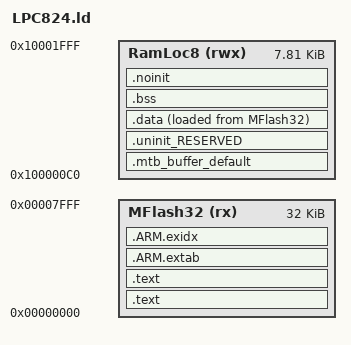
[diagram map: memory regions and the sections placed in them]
/*Based on following file
 * (c) Code Red Technologies Ltd, 2008-13
 * (c) NXP Semiconductors 2013-2015
 * Generated linker script file for LPC824
 * Created from generic_c.ld (LPCXpresso v7.4 (0 [Build 229] [2014-09-16] ))
 * By LPCXpresso v7.4.0 [Build 229] [2014-09-16]  on Fri Jan 02 03:36:48 JST 2015
 */

/* Linker script to configure memory regions. */
MEMORY
{
  /* Define each memory region */
  MFlash32 (rx) : ORIGIN = 0x0, LENGTH = 0x8000 /* 32K bytes */
  RamLoc8 (rwx) : ORIGIN = 0x10000000+0xC0, LENGTH = 0x2000-0xC0 /* 8K bytes */


}

  /* Define a symbol for the top of each memory region */
  __top_MFlash32 = 0x0 + 0x8000;
  __top_RamLoc8 = 0x10000000 + 0x2000;

GROUP(libgcc.a libc.a libstdc++.a libm.a libcr_newlib_nohost.a crti.o crtn.o crtbegin.o crtend.o)
/*GROUP(libcr_nohost.a libcr_c.a libcr_eabihelpers.a libm.a)*/
/* Linker script to place sections and symbol values. Should be used together
 * with other linker script that defines memory regions FLASH and RAM.
 * It references following symbols, which must be defined in code:
 *   Reset_Handler : Entry of reset handler
 * 
 * It defines following symbols, which code can use without definition:
 *   __exidx_start
 *   __exidx_end
 *   __etext
 *   __data_start__
 *   __preinit_array_start
 *   __preinit_array_end
 *   __init_array_start
 *   __init_array_end
 *   __fini_array_start
 *   __fini_array_end
 *   __data_end__
 *   __bss_start__
 *   __bss_end__
 *   __end__
 *   end
 *   __HeapLimit
 *   __StackLimit
 *   __StackTop
 *   __stack
 */
ENTRY(ResetISR)

SECTIONS
{

    /* MAIN TEXT SECTION */    
    .text : ALIGN(4)
    {
        FILL(0xff)
        __vectors_start__ = ABSOLUTE(.) ;
        KEEP(*(.isr_vector))
        
        /* Global Section Table */
        . = ALIGN(4) ;
        __section_table_start = .;
        __data_section_table = .;
        LONG(LOADADDR(.data));
        LONG(    ADDR(.data));
        LONG(  SIZEOF(.data));
        __data_section_table_end = .;
        __bss_section_table = .;
        LONG(    ADDR(.bss));
        LONG(  SIZEOF(.bss));
        __bss_section_table_end = .;
        __section_table_end = . ;
        /* End of Global Section Table */
        

        *(.after_vectors*)        
    } >MFlash32
    
    .text : ALIGN(4)    
    {
         *(.text*)
        *(.rodata .rodata.* .constdata .constdata.*)
        . = ALIGN(4);


        /* C++ constructors etc */
        . = ALIGN(4);
        KEEP(*(.init))
        
        . = ALIGN(4);
        __preinit_array_start = .;
        KEEP (*(.preinit_array))
        __preinit_array_end = .;
        
        . = ALIGN(4);
        __init_array_start = .;
        KEEP (*(SORT(.init_array.*)))
        KEEP (*(.init_array))
        __init_array_end = .;
        
        KEEP(*(.fini));
        
        /* .ctors */
        *crtbegin.o(.ctors)
        *crtbegin?.o(.ctors)
        *(EXCLUDE_FILE(*crtend?.o *crtend.o) .ctors)
        *(SORT(.ctors.*))
        *(.ctors)

        /* .dtors */
        *crtbegin.o(.dtors)
        *crtbegin?.o(.dtors)
        *(EXCLUDE_FILE(*crtend?.o *crtend.o) .dtors)
        *(SORT(.dtors.*))
        *(.dtors)

        *(.rodata*)

        KEEP(*(.eh_frame*))


        
    } > MFlash32

    /*
     * for exception handling/unwind - some Newlib functions (in common
     * with C++ and STDC++) use this. 
     */
    .ARM.extab : ALIGN(4)
    {
    	*(.ARM.extab* .gnu.linkonce.armextab.*)
    } > MFlash32
    __exidx_start = .;
    
    .ARM.exidx : ALIGN(4)
    {
    	*(.ARM.exidx* .gnu.linkonce.armexidx.*)
    } > MFlash32
    __exidx_end = .;
    
    _etext = .;
        
    
    /* MAIN DATA SECTION */
    
    /* Default MTB section */
    .mtb_buffer_default (NOLOAD) :
    {
       KEEP(*(.mtb*))
    } > RamLoc8 

    .uninit_RESERVED : ALIGN(4)
    {
        KEEP(*(.bss.$RESERVED*))
        . = ALIGN(4) ;
        _end_uninit_RESERVED = .;
    } > RamLoc8

	
	/* Main DATA section (RamLoc8) */
	.data : ALIGN(4)
	{
	   FILL(0xff)
	   _data = . ;
	   *(vtable)
	   *(.ramfunc*)
	   *(.data*)
	   . = ALIGN(4) ;
	   _edata = . ;
	} > RamLoc8 AT>MFlash32


    /* MAIN BSS SECTION */
    .bss : ALIGN(4)
    {
        _bss = .;
        *(.bss*)
        *(COMMON)
        . = ALIGN(4) ;
        _ebss = .;
        PROVIDE(end = .);
    } > RamLoc8
        
    
    /* DEFAULT NOINIT SECTION */
    .noinit (NOLOAD): ALIGN(4)
    {
        _noinit = .;
        *(.noinit*) 
         . = ALIGN(4) ;
        _end_noinit = .;
    } > RamLoc8
    
    PROVIDE(_pvHeapStart = DEFINED(__user_heap_base) ? __user_heap_base : .);
    PROVIDE(_vStackTop = DEFINED(__user_stack_top) ? __user_stack_top : __top_RamLoc8 - 0);
}
